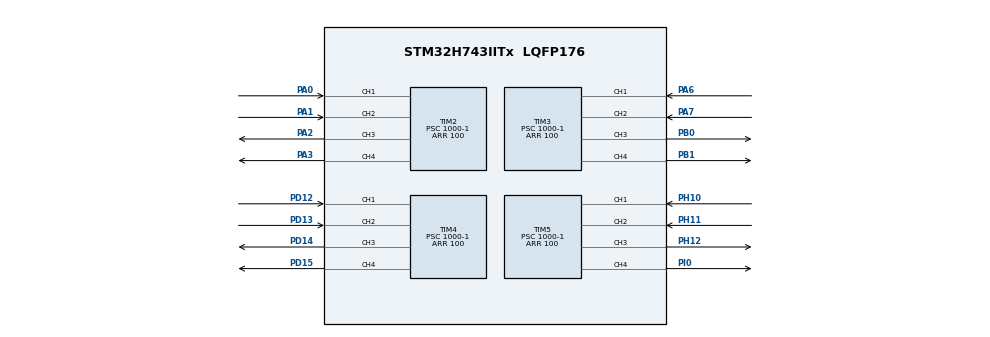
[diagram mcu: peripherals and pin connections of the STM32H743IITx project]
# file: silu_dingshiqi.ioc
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CORTEX_M7.CPU_DCache=Enabled
CORTEX_M7.CPU_ICache=Enabled
CORTEX_M7.default_mode_Activation=1
Mcu.Family=STM32H7
Mcu.Name=STM32H743IITx
Mcu.Package=LQFP176
NVIC.PriorityGroup=NVIC_PRIORITYGROUP_4
NVIC.TIM2_IRQn=true\:0\:0\:false\:false\:true\:true\:true\:true
NVIC.TIM3_IRQn=true\:0\:0\:false\:false\:true\:true\:true\:true
NVIC.TIM4_IRQn=true\:0\:0\:false\:false\:true\:true\:true\:true
NVIC.TIM5_IRQn=true\:0\:0\:false\:false\:true\:true\:true\:true
PA0.Signal=S_TIM2_CH1_ETR
PA1.Signal=S_TIM2_CH2
PA13\ (JTMS/SWDIO).Mode=Serial_Wire
PA13\ (JTMS/SWDIO).Signal=DEBUG_JTMS-SWDIO
PA14\ (JTCK/SWCLK).Mode=Serial_Wire
PA14\ (JTCK/SWCLK).Signal=DEBUG_JTCK-SWCLK
PA2.Signal=S_TIM2_CH3
PA3.Signal=S_TIM2_CH4
PA6.Signal=S_TIM3_CH1
PA7.Signal=S_TIM3_CH2
PB0.Signal=S_TIM3_CH3
PB1.Signal=S_TIM3_CH4
PC14-OSC32_IN\ (OSC32_IN).Mode=LSE-External-Oscillator
PC14-OSC32_IN\ (OSC32_IN).Signal=RCC_OSC32_IN
PC15-OSC32_OUT\ (OSC32_OUT).Mode=LSE-External-Oscillator
PC15-OSC32_OUT\ (OSC32_OUT).Signal=RCC_OSC32_OUT
PD12.Signal=S_TIM4_CH1
PD13.Signal=S_TIM4_CH2
PD14.Signal=S_TIM4_CH3
PD15.Signal=S_TIM4_CH4
PH0-OSC_IN\ (PH0).Mode=HSE-External-Oscillator
PH0-OSC_IN\ (PH0).Signal=RCC_OSC_IN
PH1-OSC_OUT\ (PH1).Mode=HSE-External-Oscillator
PH1-OSC_OUT\ (PH1).Signal=RCC_OSC_OUT
PH10.Signal=S_TIM5_CH1
PH11.Signal=S_TIM5_CH2
PH12.Signal=S_TIM5_CH3
PI0.Signal=S_TIM5_CH4
ProjectManager.HeapSize=0x200
ProjectManager.StackSize=0x400
ProjectManager.TargetToolchain=MDK-ARM V5.32
RCC.ADCFreq_Value=50390625
RCC.APB1Freq_Value=100000000
RCC.APB2Freq_Value=100000000
RCC.APB3Freq_Value=100000000
RCC.APB4Freq_Value=100000000
RCC.CortexFreq_Value=400000000
RCC.D1PPRE=RCC_APB3_DIV2
RCC.D2PPRE1=RCC_APB1_DIV2
RCC.D2PPRE2=RCC_APB2_DIV2
RCC.D3PPRE=RCC_APB4_DIV2
RCC.DIVM1=5
RCC.DIVN1=160
RCC.HCLKFreq_Value=200000000
RCC.HPRE=RCC_HCLK_DIV2
RCC.PLLSourceVirtual=RCC_PLLSOURCE_HSE
RCC.SYSCLKFreq_VALUE=400000000
RCC.SYSCLKSource=RCC_SYSCLKSOURCE_PLLCLK
RCC.USBFreq_Value=400000000
SH.S_TIM2_CH1_ETR.0=TIM2_CH1,Encoder_Interface
SH.S_TIM2_CH2.0=TIM2_CH2,Encoder_Interface
SH.S_TIM2_CH3.0=TIM2_CH3,PWM Generation3 CH3
SH.S_TIM2_CH4.0=TIM2_CH4,PWM Generation4 CH4
SH.S_TIM3_CH1.0=TIM3_CH1,Encoder_Interface
SH.S_TIM3_CH2.0=TIM3_CH2,Encoder_Interface
SH.S_TIM3_CH3.0=TIM3_CH3,PWM Generation3 CH3
SH.S_TIM3_CH4.0=TIM3_CH4,PWM Generation4 CH4
SH.S_TIM4_CH1.0=TIM4_CH1,Encoder_Interface
SH.S_TIM4_CH2.0=TIM4_CH2,Encoder_Interface
SH.S_TIM4_CH3.0=TIM4_CH3,PWM Generation3 CH3
SH.S_TIM4_CH4.0=TIM4_CH4,PWM Generation4 CH4
SH.S_TIM5_CH1.0=TIM5_CH1,Encoder_Interface
SH.S_TIM5_CH2.0=TIM5_CH2,Encoder_Interface
SH.S_TIM5_CH3.0=TIM5_CH3,PWM Generation3 CH3
SH.S_TIM5_CH4.0=TIM5_CH4,PWM Generation4 CH4
TIM2.AutoReloadPreload=TIM_AUTORELOAD_PRELOAD_ENABLE
TIM2.Channel-PWM\ Generation3\ CH3=TIM_CHANNEL_3
TIM2.Channel-PWM\ Generation4\ CH4=TIM_CHANNEL_4
TIM2.Period=100
TIM2.Prescaler=1000-1
TIM3.AutoReloadPreload=TIM_AUTORELOAD_PRELOAD_ENABLE
TIM3.Channel-PWM\ Generation3\ CH3=TIM_CHANNEL_3
TIM3.Channel-PWM\ Generation4\ CH4=TIM_CHANNEL_4
TIM3.EncoderMode=TIM_ENCODERMODE_TI12
TIM3.Period=100
TIM3.Prescaler=1000-1
TIM4.AutoReloadPreload=TIM_AUTORELOAD_PRELOAD_ENABLE
TIM4.Channel-PWM\ Generation3\ CH3=TIM_CHANNEL_3
TIM4.Channel-PWM\ Generation4\ CH4=TIM_CHANNEL_4
TIM4.EncoderMode=TIM_ENCODERMODE_TI12
TIM4.Period=100
TIM4.Prescaler=1000-1
TIM5.AutoReloadPreload=TIM_AUTORELOAD_PRELOAD_ENABLE
TIM5.Channel-PWM\ Generation3\ CH3=TIM_CHANNEL_3
TIM5.Channel-PWM\ Generation4\ CH4=TIM_CHANNEL_4
TIM5.EncoderMode=TIM_ENCODERMODE_TI12
TIM5.Period=100
TIM5.Prescaler=1000-1
TIM6.AutoReloadPreload=TIM_AUTORELOAD_PRELOAD_ENABLE
TIM6.Period=100
TIM6.Prescaler=100-1
VP_TIM6_VS_ClockSourceINT.Mode=Enable_Timer
board=custom

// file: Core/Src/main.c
/* USER CODE BEGIN Header */
/**
 ******************************************************************************
 * @file           : main.c
 * @brief          : Main program body
 ******************************************************************************
 * @attention
 *
 * Copyright (c) 2024 STMicroelectronics.
 * All rights reserved.
 *
 * This software is licensed under terms that can be found in the LICENSE file
 * in the root directory of this software component.
 * If no LICENSE file comes with this software, it is provided AS-IS.
 *
 ******************************************************************************
 */
/* USER CODE END Header */
#include "main.h"
#include "tim.h"
#include "gpio.h"

/* USER CODE BEGIN Includes */
#include "control.h"
/* USER CODE END Includes */

void SystemClock_Config(void);
static void MPU_Config(void);

int main(void)
{

  /* MPU Configuration--------------------------------------------------------*/
  MPU_Config();

  /* Enable the CPU Cache */

  /* Enable I-Cache---------------------------------------------------------*/
  SCB_EnableICache();

  /* Enable D-Cache---------------------------------------------------------*/
  SCB_EnableDCache();

  /* MCU Configuration--------------------------------------------------------*/

  /* Reset of all peripherals, Initializes the Flash interface and the Systick. */
  HAL_Init();

  /* Configure the system clock */
  SystemClock_Config();

  /* Initialize all configured peripherals */
  MX_GPIO_Init();
  MX_TIM2_Init();
  MX_TIM3_Init();
  MX_TIM4_Init();
  MX_TIM5_Init();
  MX_TIM6_Init();
  /* USER CODE BEGIN 2 */
  Motor_Init();

  /* USER CODE END 2 */

  /* Infinite loop */
  while (1)
  {

    /* USER CODE BEGIN 3 */
    Car_backward(50);
  }
  /* USER CODE END 3 */
}

void SystemClock_Config(void)
{
  RCC_OscInitTypeDef RCC_OscInitStruct = {0};
  RCC_ClkInitTypeDef RCC_ClkInitStruct = {0};

  /** Supply configuration update enable
   */
  HAL_PWREx_ConfigSupply(PWR_LDO_SUPPLY);

  /** Configure the main internal regulator output voltage
   */
  __HAL_PWR_VOLTAGESCALING_CONFIG(PWR_REGULATOR_VOLTAGE_SCALE1);

  while (!__HAL_PWR_GET_FLAG(PWR_FLAG_VOSRDY))
  {
  }

  /** Initializes the RCC Oscillators according to the specified parameters
   * in the RCC_OscInitTypeDef structure.
   */
  RCC_OscInitStruct.OscillatorType = RCC_OSCILLATORTYPE_HSE;
  RCC_OscInitStruct.HSEState = RCC_HSE_ON;
  RCC_OscInitStruct.PLL.PLLState = RCC_PLL_ON;
  RCC_OscInitStruct.PLL.PLLSource = RCC_PLLSOURCE_HSE;
  RCC_OscInitStruct.PLL.PLLM = 5;
  RCC_OscInitStruct.PLL.PLLN = 160;
  RCC_OscInitStruct.PLL.PLLP = 2;
  RCC_OscInitStruct.PLL.PLLQ = 2;
  RCC_OscInitStruct.PLL.PLLR = 2;
  RCC_OscInitStruct.PLL.PLLRGE = RCC_PLL1VCIRANGE_2;
  RCC_OscInitStruct.PLL.PLLVCOSEL = RCC_PLL1VCOWIDE;
  RCC_OscInitStruct.PLL.PLLFRACN = 0;
  if (HAL_RCC_OscConfig(&RCC_OscInitStruct) != HAL_OK)
  {
    Error_Handler();
  }

  /** Initializes the CPU, AHB and APB buses clocks
   */
  RCC_ClkInitStruct.ClockType = RCC_CLOCKTYPE_HCLK | RCC_CLOCKTYPE_SYSCLK | RCC_CLOCKTYPE_PCLK1 | RCC_CLOCKTYPE_PCLK2 | RCC_CLOCKTYPE_D3PCLK1 | RCC_CLOCKTYPE_D1PCLK1;
  RCC_ClkInitStruct.SYSCLKSource = RCC_SYSCLKSOURCE_PLLCLK;
  RCC_ClkInitStruct.SYSCLKDivider = RCC_SYSCLK_DIV1;
  RCC_ClkInitStruct.AHBCLKDivider = RCC_HCLK_DIV2;
  RCC_ClkInitStruct.APB3CLKDivider = RCC_APB3_DIV2;
  RCC_ClkInitStruct.APB1CLKDivider = RCC_APB1_DIV2;
  RCC_ClkInitStruct.APB2CLKDivider = RCC_APB2_DIV2;
  RCC_ClkInitStruct.APB4CLKDivider = RCC_APB4_DIV2;

  if (HAL_RCC_ClockConfig(&RCC_ClkInitStruct, FLASH_LATENCY_2) != HAL_OK)
  {
    Error_Handler();
  }
}

/* MPU Configuration */

void MPU_Config(void)
{
  MPU_Region_InitTypeDef MPU_InitStruct = {0};

  /* Disables the MPU */
  HAL_MPU_Disable();

  /** Initializes and configures the Region and the memory to be protected
   */
  MPU_InitStruct.Enable = MPU_REGION_ENABLE;
  MPU_InitStruct.Number = MPU_REGION_NUMBER0;
  MPU_InitStruct.BaseAddress = 0x0;
  MPU_InitStruct.Size = MPU_REGION_SIZE_4GB;
  MPU_InitStruct.SubRegionDisable = 0x87;
  MPU_InitStruct.TypeExtField = MPU_TEX_LEVEL0;
  MPU_InitStruct.AccessPermission = MPU_REGION_NO_ACCESS;
  MPU_InitStruct.DisableExec = MPU_INSTRUCTION_ACCESS_DISABLE;
  MPU_InitStruct.IsShareable = MPU_ACCESS_SHAREABLE;
  MPU_InitStruct.IsCacheable = MPU_ACCESS_NOT_CACHEABLE;
  MPU_InitStruct.IsBufferable = MPU_ACCESS_NOT_BUFFERABLE;

  HAL_MPU_ConfigRegion(&MPU_InitStruct);
  /* Enables the MPU */
  HAL_MPU_Enable(MPU_PRIVILEGED_DEFAULT);
}

void Error_Handler(void)
{
  __disable_irq();
  while (1)
  {
  }
}
